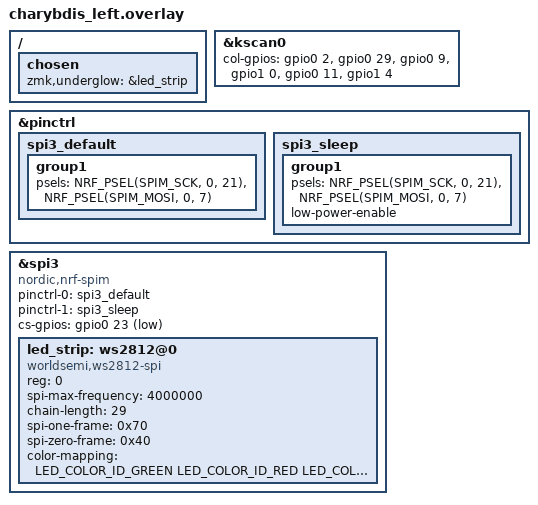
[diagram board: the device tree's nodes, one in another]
#include "charybdis.dtsi"
#include <zephyr/dt-bindings/led/led.h>

&kscan0 {
    col-gpios =
        <&gpio0 2  (GPIO_ACTIVE_HIGH | GPIO_PULL_DOWN)>,
        <&gpio0 29 (GPIO_ACTIVE_HIGH | GPIO_PULL_DOWN)>,
        <&gpio0 9  (GPIO_ACTIVE_HIGH | GPIO_PULL_DOWN)>,
        <&gpio1 0  (GPIO_ACTIVE_HIGH | GPIO_PULL_DOWN)>,
        <&gpio0 11 (GPIO_ACTIVE_HIGH | GPIO_PULL_DOWN)>,
        <&gpio1 4  (GPIO_ACTIVE_HIGH | GPIO_PULL_DOWN)>;
};

&pinctrl {
    spi3_default: spi3_default {
        group1 {
            psels = <NRF_PSEL(SPIM_SCK, 0, 21)>,
                    <NRF_PSEL(SPIM_MOSI, 0, 7)>;
        };
    };

    spi3_sleep: spi3_sleep {
        group1 {
            psels = <NRF_PSEL(SPIM_SCK, 0, 21)>,
                    <NRF_PSEL(SPIM_MOSI, 0, 7)>;
            low-power-enable;
        };
    };
};

&spi3 {
    compatible = "nordic,nrf-spim";
    status = "okay";
    pinctrl-0 = <&spi3_default>;
    pinctrl-1 = <&spi3_sleep>;
    pinctrl-names = "default", "sleep";
    cs-gpios = <&gpio0 23 GPIO_ACTIVE_LOW>;

    led_strip: ws2812@0 {
        compatible = "worldsemi,ws2812-spi";
        reg = <0>;
        spi-max-frequency = <4000000>;
        chain-length = <29>;
        spi-one-frame = <0x70>;
        spi-zero-frame = <0x40>;
        color-mapping = <LED_COLOR_ID_GREEN LED_COLOR_ID_RED LED_COLOR_ID_BLUE>;
    };
};

/ {
    chosen {
        zmk,underglow = &led_strip;
    };
};
